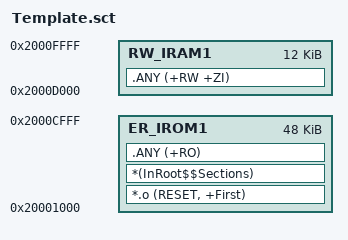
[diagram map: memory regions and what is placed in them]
; *************************************************************
; *** Scatter-Loading Description File generated by uVision ***
; *************************************************************

LR_IROM1 0x20001000 0x0000C000  {    ; load region size_region
  ER_IROM1 0x20001000 0x0000C000  {  ; load address = execution address
   *.o (RESET, +First)
   *(InRoot$$Sections)
   .ANY (+RO)
  }
  RW_IRAM1 0x2000D000 0x00003000  {  ; RW data
   .ANY (+RW +ZI)
  }
}

